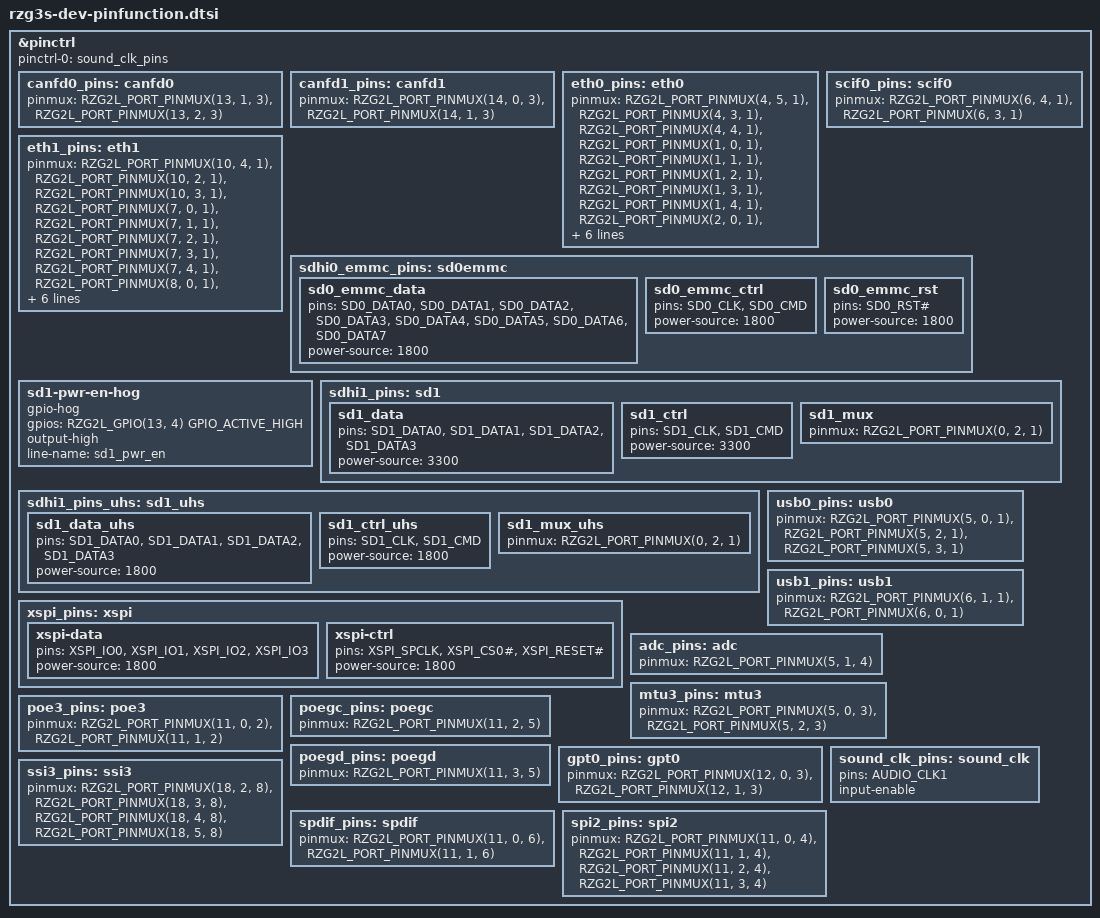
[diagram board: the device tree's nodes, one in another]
// SPDX-License-Identifier: (GPL-2.0-only OR BSD-2-Clause)
/*
 * Device Tree Source for configuration of RZ/G3S Development board pins.
 *
 * Copyright (C) 2023 Renesas Electronics Corp.
 */

#include <dt-bindings/gpio/gpio.h>
#include <dt-bindings/pinctrl/rzg2l-pinctrl.h>

&pinctrl {
	pinctrl-0 = <&sound_clk_pins>;
	pinctrl-names = "default";

	canfd0_pins: canfd0 {
		pinmux = <RZG2L_PORT_PINMUX(13, 1, 3)>, /* TX */
			 <RZG2L_PORT_PINMUX(13, 2, 3)>; /* RX */
	};

	canfd1_pins: canfd1 {
		pinmux = <RZG2L_PORT_PINMUX(14, 0, 3)>, /* TX */
			 <RZG2L_PORT_PINMUX(14, 1, 3)>; /* RX */
	};

	eth0_pins: eth0 {
		pinmux = <RZG2L_PORT_PINMUX(4, 5, 1)>, /* ET0_LINKSTA */
			 <RZG2L_PORT_PINMUX(4, 3, 1)>, /* ET0_MDC */
			 <RZG2L_PORT_PINMUX(4, 4, 1)>, /* ET0_MDIO */
			 <RZG2L_PORT_PINMUX(1, 0, 1)>, /* ET0_TXC */
			 <RZG2L_PORT_PINMUX(1, 1, 1)>, /* ET0_TX_CTL */
			 <RZG2L_PORT_PINMUX(1, 2, 1)>, /* ET0_TXD0 */
			 <RZG2L_PORT_PINMUX(1, 3, 1)>, /* ET0_TXD1 */
			 <RZG2L_PORT_PINMUX(1, 4, 1)>, /* ET0_TXD2 */
			 <RZG2L_PORT_PINMUX(2, 0, 1)>, /* ET0_TXD3 */
			 <RZG2L_PORT_PINMUX(3, 0, 1)>, /* ET0_RXC */
			 <RZG2L_PORT_PINMUX(3, 1, 1)>, /* ET0_RX_CTL */
			 <RZG2L_PORT_PINMUX(3, 2, 1)>, /* ET0_RXD0 */
			 <RZG2L_PORT_PINMUX(3, 3, 1)>, /* ET0_RXD1 */
			 <RZG2L_PORT_PINMUX(4, 0, 1)>, /* ET0_RXD2 */
			 <RZG2L_PORT_PINMUX(4, 1, 1)>; /* ET0_RXD3 */
	};

	eth1_pins: eth1 {
		pinmux = <RZG2L_PORT_PINMUX(10, 4, 1)>, /* ET1_LINKSTA */
			 <RZG2L_PORT_PINMUX(10, 2, 1)>, /* ET1_MDC */
			 <RZG2L_PORT_PINMUX(10, 3, 1)>, /* ET1_MDIO */
			 <RZG2L_PORT_PINMUX(7, 0, 1)>, /* ET1_TXC */
			 <RZG2L_PORT_PINMUX(7, 1, 1)>, /* ET1_TX_CTL */
			 <RZG2L_PORT_PINMUX(7, 2, 1)>, /* ET1_TXD0 */
			 <RZG2L_PORT_PINMUX(7, 3, 1)>, /* ET1_TXD1 */
			 <RZG2L_PORT_PINMUX(7, 4, 1)>, /* ET1_TXD2 */
			 <RZG2L_PORT_PINMUX(8, 0, 1)>, /* ET1_TXD3 */
			 <RZG2L_PORT_PINMUX(8, 4, 1)>, /* ET1_RXC */
			 <RZG2L_PORT_PINMUX(9, 0, 1)>, /* ET1_RX_CTL */
			 <RZG2L_PORT_PINMUX(9, 1, 1)>, /* ET1_RXD0 */
			 <RZG2L_PORT_PINMUX(9, 2, 1)>, /* ET1_RXD1 */
			 <RZG2L_PORT_PINMUX(9, 3, 1)>, /* ET1_RXD2 */
			 <RZG2L_PORT_PINMUX(10, 0, 1)>; /* ET1_RXD3 */
	};

	scif0_pins: scif0 {
		pinmux = <RZG2L_PORT_PINMUX(6, 4, 1)>, /* TxD */
			 <RZG2L_PORT_PINMUX(6, 3, 1)>; /* RxD */
	};

	sdhi0_emmc_pins: sd0emmc {
		sd0_emmc_data {
			pins = "SD0_DATA0", "SD0_DATA1", "SD0_DATA2", "SD0_DATA3",
			       "SD0_DATA4", "SD0_DATA5", "SD0_DATA6", "SD0_DATA7";
			power-source = <1800>;
		};

		sd0_emmc_ctrl {
			pins = "SD0_CLK", "SD0_CMD";
			power-source = <1800>;
		};

		sd0_emmc_rst {
			pins = "SD0_RST#";
			power-source = <1800>;
		};
	};

	sd1-pwr-en-hog {
		gpio-hog;
		gpios = <RZG2L_GPIO(13, 4) GPIO_ACTIVE_HIGH>;
		output-high;
		line-name = "sd1_pwr_en";
	};

	sdhi1_pins: sd1 {
		sd1_data {
			pins = "SD1_DATA0", "SD1_DATA1", "SD1_DATA2", "SD1_DATA3";
			power-source = <3300>;
		};

		sd1_ctrl {
			pins = "SD1_CLK", "SD1_CMD";
			power-source = <3300>;
		};

		sd1_mux {
			pinmux = <RZG2L_PORT_PINMUX(0, 2, 1)>; /* SD1_CD */
		};
	};

	sdhi1_pins_uhs: sd1_uhs {
		sd1_data_uhs {
			pins = "SD1_DATA0", "SD1_DATA1", "SD1_DATA2", "SD1_DATA3";
			power-source = <1800>;
		};

		sd1_ctrl_uhs {
			pins = "SD1_CLK", "SD1_CMD";
			power-source = <1800>;
		};

		sd1_mux_uhs {
			pinmux = <RZG2L_PORT_PINMUX(0, 2, 1)>; /* SD1_CD */
		};
	};

	usb0_pins: usb0 {
		pinmux = <RZG2L_PORT_PINMUX(5, 0, 1)>, /* VBUS */
			 <RZG2L_PORT_PINMUX(5, 2, 1)>, /* OVC */
			 <RZG2L_PORT_PINMUX(5, 3, 1)>; /* OTG_ID */
	};

	usb1_pins: usb1 {
		pinmux = <RZG2L_PORT_PINMUX(6, 1, 1)>, /* OVC */
			 <RZG2L_PORT_PINMUX(6, 0, 1)>; /* VBUS */
	};

	xspi_pins: xspi {
		xspi-data {
			pins = "XSPI_IO0", "XSPI_IO1", "XSPI_IO2", "XSPI_IO3";
			power-source = <1800>;
		};

		xspi-ctrl {
			pins = "XSPI_SPCLK", "XSPI_CS0#", "XSPI_RESET#";
			power-source = <1800>;
		};
	};

	adc_pins: adc {
		pinmux = <RZG2L_PORT_PINMUX(5, 1, 4)>; /* ADC_TRG */
	};

	mtu3_pins: mtu3 {
		pinmux =
			<RZG2L_PORT_PINMUX(5, 0, 3)>, /* MTIOC7A - JP1036 */
			<RZG2L_PORT_PINMUX(5, 2, 3)>; /* MTIOC7C - JP1038 */
	};

	/* Note: POE pins can be tested via J17 of SD2, but must turn off SW58. */
	poe3_pins: poe3 {
		pinmux = <RZG2L_PORT_PINMUX(11, 0, 2)>, /* POE0# - SD2_CLK - J17_6 */
			 <RZG2L_PORT_PINMUX(11, 1, 2)>; /* POE4# - SD2_CMD - J17_8 */
	};

	poegc_pins: poegc {
		pinmux = <RZG2L_PORT_PINMUX(11, 2, 5)>; /* GPT_Ext_C - SD2_DATA0 - J17_3 */
	};

	poegd_pins: poegd {
		pinmux = <RZG2L_PORT_PINMUX(11, 3, 5)>; /* GPT_Ext_D - SD2_DATA1 - J17_2 */
	};

	gpt0_pins: gpt0 {
		pinmux = <RZG2L_PORT_PINMUX(12, 0, 3)>, /* GTIOC0A - SD2_DATA2 - J17_10 */
			 <RZG2L_PORT_PINMUX(12, 1, 3)>; /* GTIOC0B - SD2_DATA3 - J17_9 */
	};

	sound_clk_pins: sound_clk {
		pins = "AUDIO_CLK1"; /* AUDIO_CLK2 not used */
		input-enable;
	};

	ssi3_pins: ssi3 {
		pinmux = <RZG2L_PORT_PINMUX(18, 2, 8)>, /* BCK */
			 <RZG2L_PORT_PINMUX(18, 3, 8)>, /* RCK */
			 <RZG2L_PORT_PINMUX(18, 4, 8)>, /* TXD */
			 <RZG2L_PORT_PINMUX(18, 5, 8)>; /* RXD */
	};

	spdif_pins: spdif {
		pinmux = <RZG2L_PORT_PINMUX(11, 0, 6)>, /* SPDIF_IN  */
			 <RZG2L_PORT_PINMUX(11, 1, 6)>; /* SPDIF_OUT */
	};

	spi2_pins: spi2 {
		pinmux = <RZG2L_PORT_PINMUX(11, 0, 4)>, /* CK */
			 <RZG2L_PORT_PINMUX(11, 1, 4)>, /* MOSI */
			 <RZG2L_PORT_PINMUX(11, 2, 4)>, /* MISO */
			 <RZG2L_PORT_PINMUX(11, 3, 4)>; /* SSL */
	};
};
